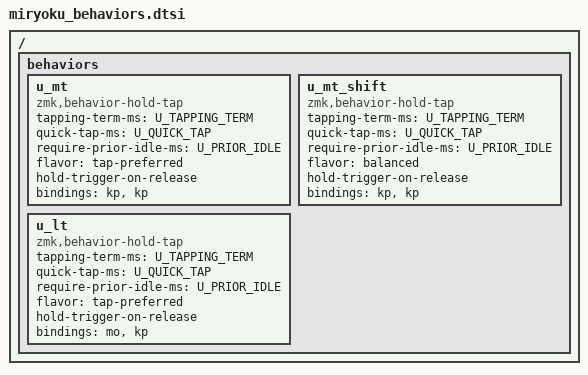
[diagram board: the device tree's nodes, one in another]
// Copyright 2022 Manna Harbour
// https://github.com/manna-harbour/miryoku

/ {
  behaviors {
    // For Ctrl, Alt, GUI - faster tap response
    u_mt: u_mt {
      compatible = "zmk,behavior-hold-tap";
      #binding-cells = <2>;
      tapping-term-ms = <U_TAPPING_TERM>;
      quick-tap-ms = <U_QUICK_TAP>;
      require-prior-idle-ms = <U_PRIOR_IDLE>;
      flavor = "tap-preferred";
      hold-trigger-on-release;
      bindings = <&kp>, <&kp>;
    };
    // For Shift - more accurate hold detection
    u_mt_shift: u_mt_shift {
      compatible = "zmk,behavior-hold-tap";
      #binding-cells = <2>;
      tapping-term-ms = <U_TAPPING_TERM>;
      quick-tap-ms = <U_QUICK_TAP>;
      require-prior-idle-ms = <U_PRIOR_IDLE>;
      flavor = "balanced";
      hold-trigger-on-release;
      bindings = <&kp>, <&kp>;
    };
    // For layer-tap (thumb keys)
    u_lt: u_lt {
      compatible = "zmk,behavior-hold-tap";
      #binding-cells = <2>;
      tapping-term-ms = <U_TAPPING_TERM>;
      quick-tap-ms = <U_QUICK_TAP>;
      require-prior-idle-ms = <U_PRIOR_IDLE>;
      flavor = "tap-preferred";
      hold-trigger-on-release;
      bindings = <&mo>, <&kp>;
    };
  };
};
